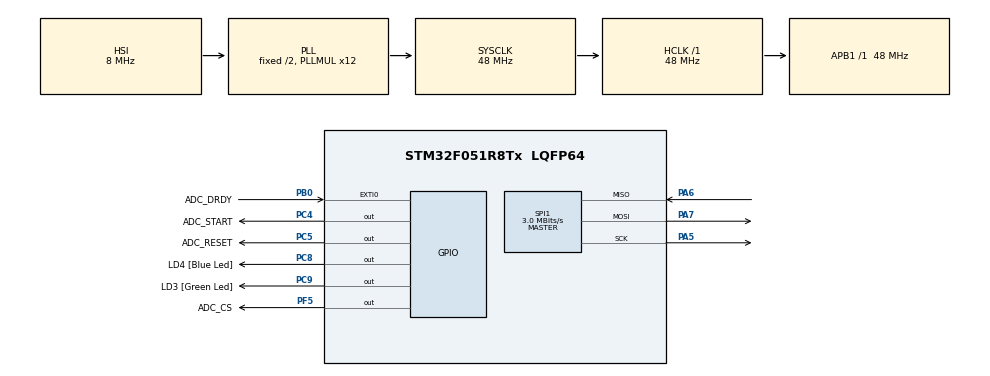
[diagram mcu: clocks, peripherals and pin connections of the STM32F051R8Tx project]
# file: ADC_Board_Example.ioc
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Mcu.Family=STM32F0
Mcu.Name=STM32F051R8Tx
Mcu.Package=LQFP64
NVIC.EXTI0_1_IRQn=true\:0\:0\:false\:false\:true\:true\:true
NVIC.SPI1_IRQn=true\:0\:0\:false\:false\:true\:true\:true
PA13.GPIO_Label=SWDIO
PA13.Mode=Serial_Wire
PA13.Signal=SYS_SWDIO
PA14.GPIO_Label=SWCLK
PA14.Mode=Serial_Wire
PA14.Signal=SYS_SWCLK
PA5.Mode=Full_Duplex_Master
PA5.Signal=SPI1_SCK
PA6.Mode=Full_Duplex_Master
PA6.Signal=SPI1_MISO
PA7.Mode=Full_Duplex_Master
PA7.Signal=SPI1_MOSI
PB0.GPIO_Label=ADC_DRDY
PB0.GPIO_ModeDefaultEXTI=GPIO_MODE_IT_FALLING
PB0.Signal=GPXTI0
PC4.GPIO_Label=ADC_START
PC4.Signal=GPIO_Output
PC5.GPIO_Label=ADC_RESET
PC5.Signal=GPIO_Output
PC8.GPIO_Label=LD4 [Blue Led]
PC8.Signal=GPIO_Output
PC9.GPIO_Label=LD3 [Green Led]
PC9.Signal=GPIO_Output
PF5.GPIO_Label=ADC_CS
PF5.GPIO_ModeDefaultOutputPP=GPIO_MODE_OUTPUT_PP
PF5.GPIO_PuPd=GPIO_NOPULL
PF5.PinState=GPIO_PIN_SET
PF5.Signal=GPIO_Output
ProjectManager.HeapSize=0x200
ProjectManager.StackSize=0x400
ProjectManager.TargetToolchain=STM32CubeIDE
RCC.AHBFreq_Value=48000000
RCC.APB1Freq_Value=48000000
RCC.APB1TimFreq_Value=48000000
RCC.HCLKFreq_Value=48000000
RCC.PLLMUL=RCC_PLL_MUL12
RCC.SYSCLKFreq_VALUE=48000000
RCC.SYSCLKSource=RCC_SYSCLKSOURCE_PLLCLK
SPI1.BaudRatePrescaler=SPI_BAUDRATEPRESCALER_16
SPI1.CLKPhase=SPI_PHASE_2EDGE
SPI1.CalculateBaudRate=3.0 MBits/s
SPI1.DataSize=SPI_DATASIZE_8BIT
SPI1.Direction=SPI_DIRECTION_2LINES
SPI1.Mode=SPI_MODE_MASTER
SPI1.VirtualType=VM_MASTER
board=STM32F0DISCOVERY

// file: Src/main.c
/* USER CODE BEGIN Header */
/**
  ******************************************************************************
  * @file           : main.c
  * @brief          : Main program body
  ******************************************************************************
  * @attention
  *
  * <h2><center>&copy; Copyright (c) 2019 STMicroelectronics.
  * All rights reserved.</center></h2>
  *
  * This software component is licensed by ST under BSD 3-Clause license,
  * the "License"; You may not use this file except in compliance with the
  * License. You may obtain a copy of the License at:
  *                        opensource.org/licenses/BSD-3-Clause
  *
  ******************************************************************************
  */
/* USER CODE END Header */

#include "main.h"
#include "spi.h"
#include "gpio.h"

/* USER CODE BEGIN Includes */
#include "ADCBoard.h"

/* USER CODE END Includes */

/* USER CODE BEGIN PV */

t_temperaturstate tempmeasurementstate= READY;	// define state

/* USER CODE END PV */

void SystemClock_Config(void);

int main(void)
{

  /* MCU Configuration--------------------------------------------------------*/

  /* Reset of all peripherals, Initializes the Flash interface and the Systick. */
  HAL_Init();

  /* Configure the system clock */
  SystemClock_Config();

  /* Initialize all configured peripherals */
  MX_GPIO_Init();
  MX_SPI1_Init();
  /* USER CODE BEGIN 2 */

  ADCinit();
  /* USER CODE END 2 */

  /* Infinite loop */
  /* USER CODE BEGIN WHILE */

  if(tempmeasurementstate==READY)
  {
	  read_temperature();

  }//tempmeasurementstate;// = ready;

  while (1)
  {
	 HAL_GPIO_TogglePin(LD3_GPIO_Port, LD3_Pin);

	  for(uint8_t i=0; i<=4; i++)
	  {
		  read_temperature();
	  }

	  if(tempmeasurementstate == NEWTEMP)
	  {
		  f_measuredtemperature = read_temperature();
		  tempmeasurementstate = READY;

	  }

	  f_Channel3Measure=calcAnalogvoltage( readsingleADCChannel(3));

    /* USER CODE END WHILE */

  }
}

void SystemClock_Config(void)
{
  RCC_OscInitTypeDef RCC_OscInitStruct = {0};
  RCC_ClkInitTypeDef RCC_ClkInitStruct = {0};

  /** Initializes the CPU, AHB and APB busses clocks
  */
  RCC_OscInitStruct.OscillatorType = RCC_OSCILLATORTYPE_HSI;
  RCC_OscInitStruct.HSIState = RCC_HSI_ON;
  RCC_OscInitStruct.HSICalibrationValue = RCC_HSICALIBRATION_DEFAULT;
  RCC_OscInitStruct.PLL.PLLState = RCC_PLL_ON;
  RCC_OscInitStruct.PLL.PLLSource = RCC_PLLSOURCE_HSI;
  RCC_OscInitStruct.PLL.PLLMUL = RCC_PLL_MUL12;
  RCC_OscInitStruct.PLL.PREDIV = RCC_PREDIV_DIV1;
  if (HAL_RCC_OscConfig(&RCC_OscInitStruct) != HAL_OK)
  {
    Error_Handler();
  }
  /** Initializes the CPU, AHB and APB busses clocks
  */
  RCC_ClkInitStruct.ClockType = RCC_CLOCKTYPE_HCLK|RCC_CLOCKTYPE_SYSCLK
                              |RCC_CLOCKTYPE_PCLK1;
  RCC_ClkInitStruct.SYSCLKSource = RCC_SYSCLKSOURCE_PLLCLK;
  RCC_ClkInitStruct.AHBCLKDivider = RCC_SYSCLK_DIV1;
  RCC_ClkInitStruct.APB1CLKDivider = RCC_HCLK_DIV1;

  if (HAL_RCC_ClockConfig(&RCC_ClkInitStruct, FLASH_LATENCY_1) != HAL_OK)
  {
    Error_Handler();
  }
}

void Error_Handler(void)
{
}

/************************ (C) COPYRIGHT STMicroelectronics *****END OF FILE****/
